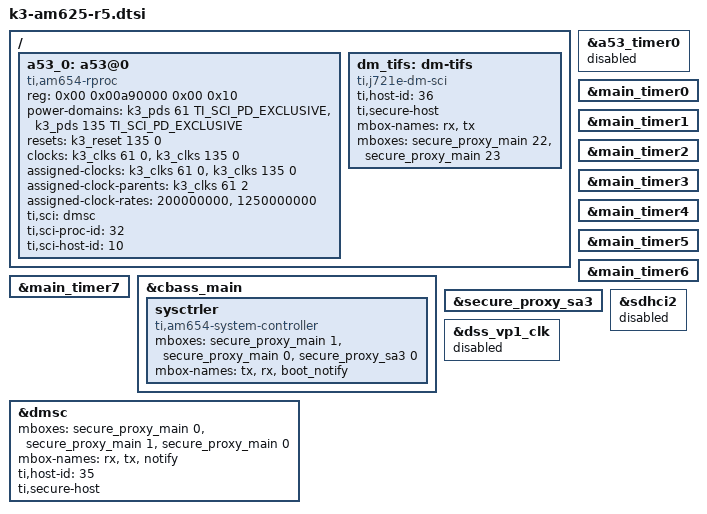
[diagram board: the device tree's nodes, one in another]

&a53_timer0 {
	status = "disabled";
};

&main_timer0 {
	/delete-property/ assigned-clocks;
	/delete-property/ assigned-clock-parents;
};

&main_timer1 {
	/delete-property/ assigned-clocks;
	/delete-property/ assigned-clock-parents;
};

&main_timer2 {
	/delete-property/ assigned-clocks;
	/delete-property/ assigned-clock-parents;
};

&main_timer3 {
	/delete-property/ assigned-clocks;
	/delete-property/ assigned-clock-parents;
};

&main_timer4 {
	/delete-property/ assigned-clocks;
	/delete-property/ assigned-clock-parents;
};

&main_timer5 {
	/delete-property/ assigned-clocks;
	/delete-property/ assigned-clock-parents;
};

&main_timer6 {
	/delete-property/ assigned-clocks;
	/delete-property/ assigned-clock-parents;
};

&main_timer7 {
	/delete-property/ assigned-clocks;
	/delete-property/ assigned-clock-parents;
};

&cbass_main {
	sysctrler: sysctrler {
		compatible = "ti,am654-system-controller";
		mboxes= <&secure_proxy_main 1>, <&secure_proxy_main 0>, <&secure_proxy_sa3 0>;
		mbox-names = "tx", "rx", "boot_notify";
	};
};

&secure_proxy_sa3 {
	/* We require this for boot handshake */
	status = "okay";
};

/ {
	a53_0: a53@0 {
		compatible = "ti,am654-rproc";
		reg = <0x00 0x00a90000 0x00 0x10>;
		power-domains = <&k3_pds 61 TI_SCI_PD_EXCLUSIVE>,
				<&k3_pds 135 TI_SCI_PD_EXCLUSIVE>;
		resets = <&k3_reset 135 0>;
		clocks = <&k3_clks 61 0>, <&k3_clks 135 0>;
		clock-names = "gtc", "core";
		assigned-clocks = <&k3_clks 61 0>, <&k3_clks 135 0>;
		assigned-clock-parents = <&k3_clks 61 2>;
		assigned-clock-rates = <200000000>, <1250000000>;
		ti,sci = <&dmsc>;
		ti,sci-proc-id = <32>;
		ti,sci-host-id = <10>;
	};

	dm_tifs: dm-tifs {
		compatible = "ti,j721e-dm-sci";
		ti,host-id = <36>;
		ti,secure-host;
		mbox-names = "rx", "tx";
		mboxes= <&secure_proxy_main 22>,
			<&secure_proxy_main 23>;
	};
};

&dmsc {
	mboxes = <&secure_proxy_main 0>,
		 <&secure_proxy_main 1>,
		 <&secure_proxy_main 0>;
	mbox-names = "rx", "tx", "notify";
	ti,host-id = <35>;
	ti,secure-host;
};

&sdhci2 {
	/* Doesn't work currently, no clocks defined */
	status = "disabled";
};

&dss_vp1_clk {
	/* Doesn't work, no support for input clock */
	status = "disabled";
};
